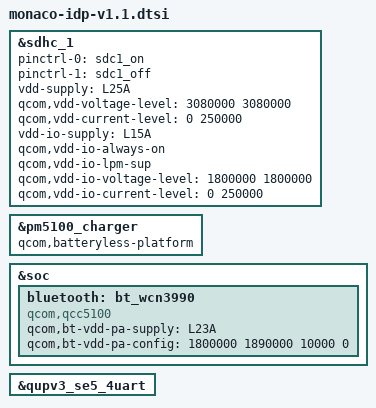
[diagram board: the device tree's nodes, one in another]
#include <dt-bindings/interrupt-controller/arm-gic.h>
#include <dt-bindings/clock/qcom,gcc-monaco.h>
#include <dt-bindings/interconnect/qcom,monaco.h>
#include <dt-bindings/regulator/qcom,rpm-smd-regulator.h>
#include "camera/monaco-camera.dtsi"
#include "camera/monaco-camera-sensor-idp.dtsi"

#include "monaco-idp-v1-common.dtsi"
#include "slate.dtsi"
#include "monaco-slate-audio-overlay.dtsi"
&sdhc_1 {
	status = "ok";

	pinctrl-names = "default", "sleep";
	pinctrl-0 = <&sdc1_on>;
	pinctrl-1 = <&sdc1_off>;

	vdd-supply = <&L25A>;
	qcom,vdd-voltage-level = <3080000 3080000>;
	qcom,vdd-current-level = <0 250000>;

	vdd-io-supply = <&L15A>;
	qcom,vdd-io-always-on;
	qcom,vdd-io-lpm-sup;
	qcom,vdd-io-voltage-level = <1800000 1800000>;
	qcom,vdd-io-current-level = <0 250000>;
};

&pm5100_charger {
	qcom,batteryless-platform;
};

&soc {
	bluetooth: bt_wcn3990 {
		compatible = "qcom,qcc5100";
		qcom,bt-vdd-pa-supply = <&L23A>; /* CH0 */

		qcom,bt-vdd-pa-config = <1800000 1890000 10000 0>;
		status = "ok";
	};
};

&qupv3_se5_4uart {
	status = "ok";
};

